# GD32L23x register map
File version: 1.0
GD32L23x ARM 32-bit Cortex-M23 Microcontroller based device
CPU: CM23 r0p0, little endian, MPU, FPU, 4 interrupt priority bits
Registers are 32-bit, read-write, reset 0x0 unless marked. A register's access mark holds for its fields unless they carry their own. Offsets are from the block's base; lines under a group give offsets from that group; [hi:lo] are bit positions; {n}, {i} and the like mark numbered series; 'fields as' and 'values as' point back to an identical list; <NAME> marks a mode.

## Memory map
0x40000000 TIMER1 size 0x400 — General-purpose-timers
0x40000400 TIMER2 size 0x400 — General-purpose-timers
0x40001000 TIMER5 size 0x400 — Basic-timers
0x40001400 TIMER6 size 0x400 — Basic-timers
0x40001800 TIMER11 size 0x400
0x40002400 SLCD size 0x400 — Segment LCD controller
0x40002800 RTC size 0x400 — Real-time clock
0x40002C00 WWDGT size 0x400 — Window watchdog timer
0x40003000 FWDGT size 0x400 — free watchdog timer
0x40003800 SPI1 size 0x400 — Serial Peripheral Interface 1
0x40004400 USART1 size 0x400 — Universal synchronous asynchronous receiver transmitter
0x40004C00 UART3 size 0x400 — Universal synchronous asynchronous receiver transmitter
0x40005000 UART4 size 0x400 — Universal synchronous asynchronous receiver transmitter
0x40005400 I2C0 size 0x400 — Inter integrated circuit
0x40005800 I2C1 size 0x400
0x40005C00 USBD size 0x400 — Universal serial bus full-speed device interface
0x40007000 PMU size 0x400 — Power management unit
0x40007400 DAC size 0x400 — Digital-to-analog converter
0x40008000 LPUART size 0x400 — Low-power Universal synchronous asynchronous receiver transmitter
0x40009400 LPTIMER size 0x400 — Low power timers
0x4000C000 I2C2 size 0x400
0x4000C800 CTC size 0x400 — Clock trim controller
0x40010000 SYSCFG size 0x400 — System configuration controller
0x40010030 VREF size 0x400
0x40010400 EXTI size 0x400 — External interrupt/event controller
0x40012400 ADC size 0x400 — Analog to digital converter
0x40013000 SPI0 size 0x400 — Serial peripheral interface
0x40013800 USART0 size 0x400 — Universal synchronous asynchronous receiver transmitter
0x40014C00 TIMER8 size 0x400 — General-purpose-timers
0x40015800 DBGMCU size 0x400 — Debug support
0x40017C00 CMP size 0x400 — Comparator
0x40020000 DMA size 0x400 — DMA controller
0x40020800 DMAMUX size 0x400 — DMAMUX controller
0x40021000 RCU size 0x400 — Reset and clock unit
0x40022000 FMC size 0x400
0x40023000 CRC size 0x400 — cyclic redundancy check calculation unit
0x48000000 GPIOA size 0x400 — General-purpose I/Os
0x48000400 GPIOB size 0x400 — General-purpose I/Os
0x48000800 GPIOC size 0x400 — General-purpose I/Os
0x48000C00 GPIOD size 0x400 — General-purpose I/Os
0x48001400 GPIOF size 0x400 — General-purpose I/Os
0x50060000 CAU size 0x400 — Cryptographic acceleration unit
0x50060800 TRNG size 0x400 — Ture random number generator
0xE000E100 NVIC size 0xF00 — Nested Vectored Interrupt Controller

## Interrupts
0 WWDGT
1 LVD (EXTI)
2 RTC_Tamper_Timestamp (RTC)
3 RTC_WAKE (RTC)
4 FMC
5 RCU_CTC (CTC, RCU)
6 EXTI0 (EXTI)
7 EXTI01 (EXTI)
8 EXTI2 (EXTI)
9 EXTI3 (EXTI)
10 EXTI4 (EXTI)
11 DMA_Channel0 (DMA)
12 DMA_Channel1 (DMA)
13 DMA_Channel2 (DMA)
14 DMA_Channel3 (DMA)
15 DMA_Channel4 (DMA)
16 DMA_Channel5 (DMA)
17 DMA_Channel6 (DMA)
18 ADC
19 USBD_HP (USBD)
20 USBD_LP (USBD)
21 TIMER1
22 TIMER2
23 TIMER0_BRK_TIMER8 (TIMER8)
24 TIMER8 (TIMER11)
25 TIMER5
26 TIMER6
27 USART0
28 USART1
29 USART3 (UART3)
30 UART4
31 I2C0_EV (I2C0)
32 I2C0_ER (I2C0)
33 I2C1_EV (I2C1)
34 I2C1_ER (I2C1)
35 SPI0
36 SPI1
37 DAC
39 I2C2_EV (I2C2)
40 I2C2_ER (I2C2)
41 RTC_Alarm (RTC)
42 USBD_WKUP (USBD)
43 EXTI5_9 (EXTI)
47 EXTI10_15 (EXTI)
55 DMA_MUX (DMAMUX)
56 CMP0 (CMP)
57 CMP1 (CMP)
58 I2C0_WAKE (I2C0)
59 I2C2_WAKE (I2C2)
60 USART0_WAKE (USART0)
61 LPUART
62 CAU
63 TRNG
64 SLCD
65 USART1_WAKE (USART1)
66 I2C1_WAKE (I2C1)
67 LPUART_WAKE (LPUART)
68 LPTIMER

## CRC — cyclic redundancy check calculation unit
Base 0x40023000
0x00 DATA reset 0xFFFFFFFF
  [31:0] DATA — CRC calculation result bits
0x04 FDATA — Free data register
  [7:0] FDATA — General-purpose 8-bit data register bits
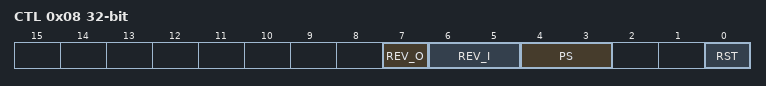
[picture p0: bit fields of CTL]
0x08 CTL — Control register
  [7] REV_O — Reverse output data value in bit order
  [6:5] REV_I — Reverse type for input data
  [4:3] PS — Size of polynomial
  [0] RST — reset bit
0x10 IDATA reset 0xFFFFFFFF — Initialization data register
  [31:0] IDATA — Configurable initial CRC data value
0x14 POLY reset 0x4C11DB7 — Polynomial register
  [31:0] POLY — User configurable polynomial value
